# AVR32DU28 device description
Architecture: AVR8X; Family: AVR
Registers are 8-bit, read-write, reset 0x0 unless marked. A register's access mark holds for its fields unless they carry their own. Offsets are from the block's base; [hi:lo] are bit positions; lines under a group give offsets from that group; {n}, {i} and the like mark numbered series; 'fields as' and 'values as' point back to an identical list; <NAME> marks a mode.

## USB_EP_TABLE — USB Device Controller EP_TABLE
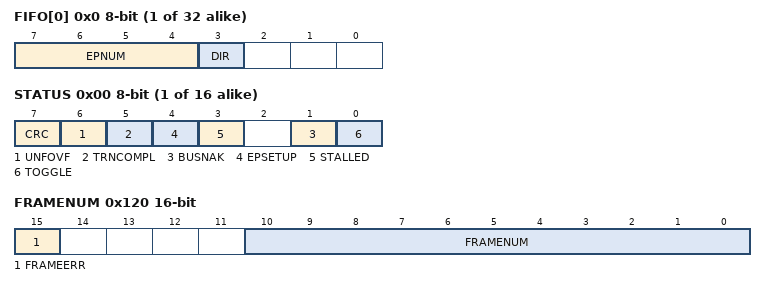
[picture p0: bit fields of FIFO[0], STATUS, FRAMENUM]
{0x0+i} FIFO[{i}] (i=0..31) ro reset not defined — FIFO Pointer Table
  [7:4] EPNUM — Endpoint Number
  [3] DIR — Endpoint Direction
    0=OUT (OUT Endpoint); 1=IN (In Endpoint)
{0x20+0x100*i} EP[{i}] (i=0..15) group — USB Device Controller EP
  0x00 OUT group — USB Device Controller OUT
    0x00 STATUS reset not defined (modes: DEFAULT when USB.CTRL.TYPE=0x00 0x01 0x02; ISO when USB.CTRL.TYPE=0x03) — Endpoint Status
      [6] UNFOVF — Underflow/Overflow EP
      [5] TRNCOMPL — Transaction Complete
      [1] BUSNAK — Data Buffer NAK
      [4] EPSETUP <DEFAULT> — EP Setup Complete
      [3] STALLED <DEFAULT> — EP Stalled
      [0] TOGGLE <DEFAULT> — Data Toggle
        0=DATA0 (DATA0 PID in next transaction); 1=DATA1 (DATA1 PID in next transaction)
      [7] CRC <ISO> — CRC Error
    0x01 CTRL reset not defined (modes: DEFAULT when USB.CTRL.TYPE=0x00 0x01 0x02; ISO when USB.CTRL.TYPE=0x03) — Endpoint Control
      [7:6] TYPE — Endpoint type
        0=DISABLE (Endpoint Disabled); 1=CONTROL; 2=BULKINT (Bulk or Interrupt); 3=ISO (Isochronous)
      [5] MULTIPKT — Multipacket transfer enable
      [3] TCDSBL — TRNCOMPL Interrupt Disable
      [4] AZLP <DEFAULT> — Automatic zero length packet
      [2] DOSTALL <DEFAULT> — Endpoint will respond with STALL
      [1:0] BUFSIZE <DEFAULT> — Data Size default
        0=BUF8 (8 bytes buffer size); 1=BUF16 (16 bytes buffer size); 2=BUF32 (32 bytes buffer size); 3=BUF64 (64 bytes buffer size)
      [2:0] BUFSIZE <ISO> — Data Size isochronous
        0=BUF8 (8 bytes buffer size); 1=BUF16 (16 bytes buffer size); 2=BUF32 (32 bytes buffer size); 3=BUF64 (64 bytes buffer size); 4=BUF128 (128 bytes buffer size); 5=BUF256 (256 bytes buffer size); 6=BUF512 (512 bytes buffer size); 7=BUF1023 (1023 bytes buffer size)
    0x02 CNT 16-bit reset not defined — Endpoint Byte Count
    0x04 DATAPTR 16-bit reset not defined — Endpoint Data Pointer
      [15:0] DATAPTR — Endpoint data pointer
    0x06 MCNT 16-bit reset not defined — Endpoint Multi-packet Byte Count
      [15:0] MCNT — Multi-packet byte count
  0x08 IN group — USB Device Controller IN
    0x00 STATUS reset not defined (modes: DEFAULT when USB.CTRL.TYPE=0x00 0x01 0x02; ISO when USB.CTRL.TYPE=0x03) — Endpoint Status
      fields as EP[0].OUT.STATUS
    0x01 CTRL reset not defined (modes: DEFAULT when USB.CTRL.TYPE=0x00 0x01 0x02; ISO when USB.CTRL.TYPE=0x03) — Endpoint Control
      fields as EP[0].OUT.CTRL
    0x02 CNT 16-bit reset not defined — Endpoint Byte Count
    0x04 DATAPTR 16-bit reset not defined — Endpoint Data Pointer
      [15:0] DATAPTR — Endpoint data pointer
    0x06 MCNT 16-bit reset not defined — Endpoint Multi-packet Byte Count
      [15:0] MCNT — Multi-packet byte count
0x120 FRAMENUM 16-bit ro reset not defined — FRAMENUM count
  [15] FRAMEERR — Frame Error
  [10:0] FRAMENUM — Frame Number

## USB — USB Device Controller
Instances: USB0 0xC00
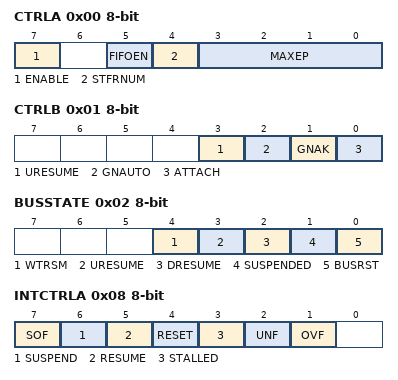
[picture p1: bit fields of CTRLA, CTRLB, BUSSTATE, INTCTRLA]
0x00 CTRLA — Control A
  [7] ENABLE — USB Enable
  [5] FIFOEN — Transaction Complete FIFO Enable
  [4] STFRNUM — Store Frame Number Enable
  [3:0] MAXEP — Maximum Endpoint Address
0x01 CTRLB — Control B
  [3] URESUME — Send Upstream Resume
  [2] GNAUTO — Set GNAK Automatically after SETUP
  [1] GNAK — Respond with NAK on all Endpoints
  [0] ATTACH
0x02 BUSSTATE ro
  [4] WTRSM — Wait Time Resume
  [3] URESUME — Upstream Resume
  [2] DRESUME — Downstram Resume
  [1] SUSPENDED — Bus Suspended
  [0] BUSRST — Bus Reset
0x03 ADDR — Address
  [6:0] ADDR — Device Address
0x04 FIFOWP reset 0xFF — FIFO Write Pointer
  [4:0] FIFOWP
0x05 FIFORP reset 0xFF — FIFO Read Pointer
  [4:0] FIFORP
0x06 EPPTR 16-bit — Endpoint Configuration Table Pointer
  [15:0] EPPTR ro
0x08 INTCTRLA — Interrupt Control A
  [7] SOF — Start Of Frame Interrupt Enable
  [6] SUSPEND — Suspend Interrupt Enable
  [5] RESUME — Resume Interrupt Enable
  [4] RESET — Reset Interrupt Enable
  [3] STALLED — STALL Interrupt Enable
  [2] UNF — Underflow Interrupt Enable
  [1] OVF — Overflow Interrupt Enable
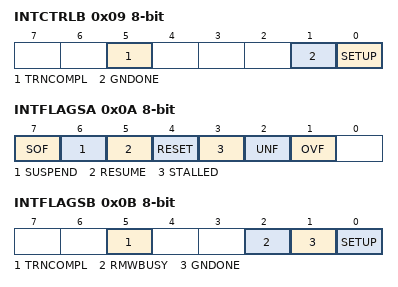
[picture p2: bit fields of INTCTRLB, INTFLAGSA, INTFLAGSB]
0x09 INTCTRLB — Interrupt Control B
  [5] TRNCOMPL — Transaction Complete Interrupt Enable
  [1] GNDONE — GNAK Operation Done Interrupt Enable
  [0] SETUP — SETUP Transaction Complete Interrupt Enable
0x0A INTFLAGSA — Interrupt Flags A
  [7] SOF — Start Of Frame Interrupt Flag
  [6] SUSPEND — Suspend Interrupt Flag
  [5] RESUME — Resume Interrupt Flag
  [4] RESET — Reset Interrupt Flag
  [3] STALLED — STALL Interrupt Flag
  [2] UNF — Underflow Interrupt Flag
  [1] OVF — Overflow Interrupt Flag
0x0B INTFLAGSB — Interrupt Flags B
  [5] TRNCOMPL — Transaction Complete Interrupt Flag
  [2] RMWBUSY — RMW Busy Flag
  [1] GNDONE — GNAK Operation Done Interrupt Flag
  [0] SETUP — SETUP Transaction Complete Interrupt Flag
{0x40+0x40*i} STATUS[{i}] (i=0..15) group — USB Device Controller STATUS
  0x00 OUTCLR wo — Endpoint n OUT Status Clear
    [7:0] RMWSTATUS — Read-Modify-Write Endpoint STATUS
  0x01 OUTSET wo — Endpoint n OUT Status Set
    [7:0] RMWSTATUS — Read-Modify-Write Endpoint STATUS
  0x02 INCLR wo — Endpoint n IN Status Clear
    [7:0] RMWSTATUS — Read-Modify-Write Endpoint STATUS
  0x03 INSET wo — Endpoint n IN Status Set
    [7:0] RMWSTATUS — Read-Modify-Write Endpoint STATUS

## USERROW
Instances: USERROW 0x1200
{0x0+i} USERROW[{i}] (i=0..511) reset not defined

## VPORT — Virtual Ports
Instances: VPORTA 0x0000, VPORTC 0x0008, VPORTD 0x000C, VPORTF 0x0014
0x00 DIR — Data Direction
0x01 OUT — Output Value
0x02 IN — Input Value
0x03 INTFLAGS — Interrupt Flags
  [7:0] INT — Pin Interrupt Flag

## VREF — Voltage reference
Instances: VREF 0x00B0
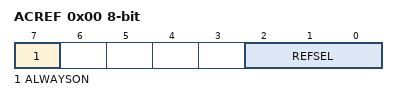
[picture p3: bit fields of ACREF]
0x00 ACREF — ADC0 Reference
  [7] ALWAYSON
  [2:0] REFSEL — Reference select
    0=1V024 (Internal 1.024V reference); 1=2V048 (Internal 2.048V reference); 2=4V096 (Internal 4.096V reference); 3=2V500 (Internal 2.500V reference); 5=VDD (VDD as reference); 6=VREFA (External reference on VREFA pin)

## WDT — Watch-Dog Timer
Instances: WDT 0x0100
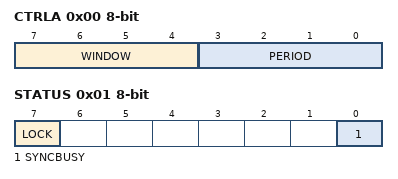
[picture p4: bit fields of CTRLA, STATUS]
0x00 CTRLA — Control A
  [7:4] WINDOW
    0=OFF; 1=8CLK (8 cycles (8ms)); 2=16CLK (16 cycles (16ms)); 3=32CLK (32 cycles (32ms)); 4=64CLK (64 cycles (64ms)); 5=128CLK (128 cycles (0.128s)); 6=256CLK (256 cycles (0.256s)); 7=512CLK (512 cycles (0.512s)); 8=1KCLK (1K cycles (1.0s)); 9=2KCLK (2K cycles (2.0s)); 10=4KCLK (4K cycles (4.1s)); 11=8KCLK (8K cycles (8.2s))
  [3:0] PERIOD
    values as WINDOW
0x01 STATUS
  [7] LOCK — Lock enable
  [0] SYNCBUSY ro — Syncronization busy
